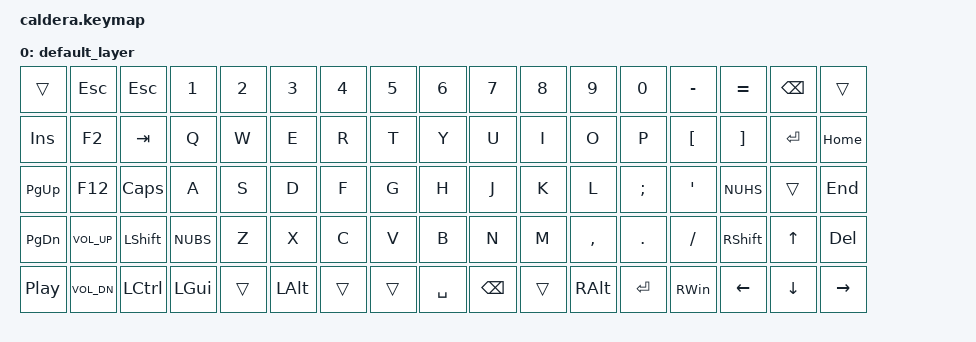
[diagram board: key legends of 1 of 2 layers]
#include <behaviors.dtsi>
#include <dt-bindings/zmk/keys.h>
#include <dt-bindings/zmk/bt.h>

/ {
        keymap {
                compatible = "zmk,keymap";

                default_layer {
                        bindings = <
   &trans            &kp ESC       &kp ESC    &kp N1     &kp N2  &kp N3    &kp N4  &kp N5  &kp N6               &kp N7    &kp N8  &kp N9     &kp N0    &kp MINUS  &kp EQUAL  &kp BSPC  &trans
   &kp INS           &kp F2        &kp TAB    &kp Q      &kp W   &kp E     &kp R   &kp T   &kp Y                &kp U     &kp I   &kp O      &kp P     &kp LBKT   &kp RBKT   &kp RET   &kp HOME 
   &kp PG_UP         &kp F12       &kp CLCK   &kp A      &kp S   &kp D     &kp F   &kp G   &kp H                &kp J     &kp K   &kp L      &kp SEMI  &kp APOS   &kp NUHS   &trans    &kp END 
   &kp PG_DN         &kp C_VOL_UP  &kp LSHFT  &kp NUBS   &kp Z   &kp X     &kp C   &kp V   &kp B                &kp N     &kp M   &kp COMMA  &kp DOT   &kp FSLH   &kp RSHFT  &kp UP    &kp DEL 
   &kp C_PLAY_PAUSE  &kp K_VOL_DN  &kp LCTRL  &kp LGUI   &trans  &kp LALT  &trans  &trans  &kp SPACE            &kp BSPC  &trans  &kp RALT   &kp RET   &kp RWIN   &kp LEFT   &kp DOWN  &kp RIGHT 
                        >;
                };
                lower_layer {
                        bindings = <
   &trans    &bt BT_SEL 0   &bt BT_SEL 1   &bt BT_SEL 2   &bt BT_SEL 3   &bt BT_SEL 4           &trans    &trans    &trans   &trans   &trans  &bt BT_CLR
   &trans    &trans         &trans         &trans         &trans         &trans                 &trans    &trans    &trans   &trans   &trans  &trans
   &trans    &trans         &trans         &kp LPAR       &kp RPAR       &trans                 &trans    &kp LBKT  &kp RBKT &kp MINUS   &kp EQUAL  &trans
   &trans    &trans         &trans         &trans         &trans         &trans                 &trans    &trans    &trans   &trans   &trans  &trans
                        >;
                };
        };
};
